# STM32WBA52 register map
File version: 0.1
CPU: CM33 r0p1, little endian, MPU, FPU, 4 interrupt priority bits
Registers are 32-bit, read-write, reset 0x0 unless marked. A register's access mark holds for its fields unless they carry their own. Offsets are from the block's base; [hi:lo] are bit positions; {n}, {i} and the like mark numbered series.

## DBGMCU — Microcontroller debug unit
Base 0xE0044000
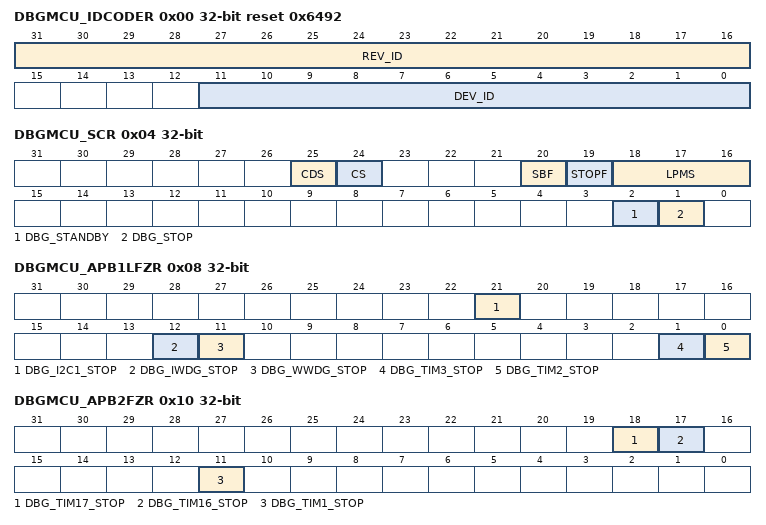
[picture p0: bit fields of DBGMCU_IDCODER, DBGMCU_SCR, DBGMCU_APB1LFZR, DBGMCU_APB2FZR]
0x00 DBGMCU_IDCODER ro reset 0x6492 (reset mask 0xFFFF) — DBGMCU identity code register
  [31:16] REV_ID — Revision ID
    0x1000=Revision A
  [11:0] DEV_ID — Device ID
    0x492=STM32WBA5xxx
0x04 DBGMCU_SCR access per field — DBGMCU status and configuration register
  [25] CDS ro — CPU DeepSleep
    0=CPU not in DeepSleep; 1=CPU in DeepSleep
  [24] CS ro — CPU Sleep
    0=CPU not in Sleep; 1=CPU in Sleep
  [20] SBF ro — Device Standby flag
    0=Device not in Standby mode; 1=Device in Standby mode
  [19] STOPF ro — Device Stop flag
    0=device not in Stop mode; 1=device in Stop mode
  [18:16] LPMS ro — Device low power mode selected 10x: Standby mode others reserved
    0=Stop 0 mode; 1=Stop 1 mode
  [2] DBG_STANDBY rw — Allows debug in Standby mode Write access can be protected by PWR_SECCFGR.LPMSEC. The CPU debug and DBGMCU clocks remain active and the HSI16 oscillator is used as system clock, the supply and SRAM memory content is maintained during Standby debug mode, allowing CPU debug capability. On exit from Standby mode, a standby reset is performed.
    0=Normal Standby mode operation, all clocks are disabled automatically in Stop mode and core is powered down; 1=Core power maintained and CPU debug clock enabled in Standby mode, all other are under reset in Stop mode, except for DBGMCU
  [1] DBG_STOP rw — Allows debug in Stop mode Write access can be protected by PWR_SECCFGR.LPMSEC. The CPU debug and DBGMCU clocks remain active and the HSI16 oscillators is used as system clock during Stop debug mode, allowing CPU debug capability. On exit from Stop mode, the clock settings are set to the Stop mode exit state.
    0=Normal Stop mode operation, all clocks are disabled automatically in Stop mode; 1=CPU debug clock enabled in Stop mode, all other peripheral clocks are disabled automatically in Stop mode, except for DBGMCU
0x08 DBGMCU_APB1LFZR — DBGMCU APB1L peripheral freeze register
  [21] DBG_I2C1_STOP — I2C1 SMBUS timeout stop in CPU debug Write access can be protected by GTZC_TZSC.I2C1SEC.
    0=Normal operation. I2C1 SMBUS timeout continues to operate while CPU is in debug mode.; 1=Stop in debug. I2C1 SMBUS timeout is frozen while CPU is in debug mode.
  [12] DBG_IWDG_STOP — IWDG stop in CPU debug Write access can be protected by GTZC_TZSC.IWDGSEC.
    0=Normal operation. IWDG continues to operate while CPU is in debug mode.; 1=Stop in debug. IWDG is frozen while CPU is in debug mode.
  [11] DBG_WWDG_STOP — WWDG stop in CPU debug Write access can be protected by GTZC_TZSC.WWDGSEC
    0=Normal operation. WWDG continues to operate while CPU is in debug mode.; 1=Stop in debug. WWDG is frozen while CPU is in debug mode.
  [1] DBG_TIM3_STOP — TIM3 stop in CPU debug Write access can be protected by GTZC_TZSC.TIM3SEC.
    0=Normal operation. TIM3 continues to operate while CPU is in debug mode.; 1=Stop in debug. TIM3 is frozen while CPU is in debug mode.
  [0] DBG_TIM2_STOP — TIM2 stop in CPU debug Write access can be protected by GTZC_TZSC.TIM2SEC.
    0=Normal operation. TIM2 continues to operate while CPU is in debug mode.; 1=Stop in debug. TIM2 is frozen while CPU is in debug mode.
0x0C DBGMCU_APB1HFZR — DBGMCU APB1H peripheral freeze register
  [5] DBG_LPTIM2_STOP — LPTIM2 stop in CPU debug Write access can be protected by GTZC_TZSC.LPTIM2SEC.
    0=Normal operation. LPTIM2 continues to operate while CPU is in debug mode.; 1=Stop in debug. LPTIM2 is frozen while CPU is in debug mode.
0x10 DBGMCU_APB2FZR — DBGMCU APB2 peripheral freeze register
  [18] DBG_TIM17_STOP — TIM17 stop in CPU debug Write access can be protected by GTZC_TZSC.TIM17SEC.
    0=Normal operation. TIM17 continues to operate while CPU is in debug mode.; 1=Stop in debug. TIM17 is frozen while CPU is in debug mode.
  [17] DBG_TIM16_STOP — TIM16 stop in CPU debug Write access can be protected by GTZC_TZSC.TIM16SEC.
    0=Normal operation. TIM16 continues to operate while CPU is in debug mode.; 1=Stop in debug. TIM16 is frozen while CPU is in debug mode.
  [11] DBG_TIM1_STOP — TIM1 stop in CPU debug Write access can be protected by GTZC_TZSC.TIM1SEC.
    0=Normal operation. TIM1 continues to operate while CPU is in debug mode.; 1=Stop in debug. TIM1 is frozen while CPU is in debug mode.
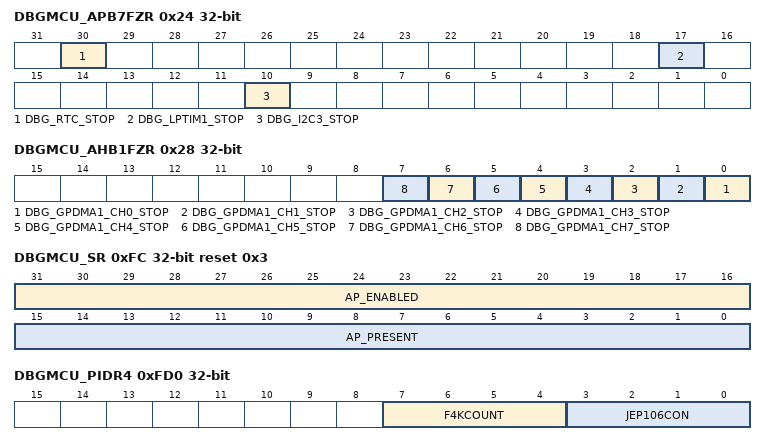
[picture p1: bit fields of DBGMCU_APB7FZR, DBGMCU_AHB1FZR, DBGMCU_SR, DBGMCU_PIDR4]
0x24 DBGMCU_APB7FZR — DBGMCU APB7 peripheral freeze register
  [30] DBG_RTC_STOP — RTC stop in CPU debug Access can be protected by GTZC_TZSC.TIM17SEC. Can only be accessed secure when one or more features in the RTC or TAMP is/are secure.
    0=Normal operation. RTC continues to operate while CPU is in debug mode.; 1=Stop in debug. RTC is frozen while CPU is in debug mode.
  [17] DBG_LPTIM1_STOP — LPTIM1 stop in CPU debug Access can be protected by GTZC_TZSC.LPTIM1SEC.
    0=Normal operation. LPTIM1 continues to operate while CPU is in debug mode.; 1=Stop in debug. LPTIM1 is frozen while CPU is in debug mode.
  [10] DBG_I2C3_STOP — I2C3 stop in CPU debug Access can be protected by GTZC_TZSC.I2C3SEC.
    0=Normal operation. I2C3 continues to operate while CPU is in debug mode.; 1=Stop in debug. I2C3 is frozen while CPU is in debug mode.
0x28 DBGMCU_AHB1FZR — DBGMCU AHB1 peripheral freeze register
  [n] DBG_GPDMA1_CH{n}_STOP (n=0..7) — GPDMA 1 channel {n} stop in CPU debug Write access can be protected by GPDMA_SECCFGR.SEC{n}.
    0=Normal operation. GPDMA 1 channel {n} continues to operate while CPU is in debug mode.; 1=Stop in debug. GPDMA 1 channel {n} is frozen while CPU is in debug mode.
0xFC DBGMCU_SR ro reset 0x3 (reset mask 0xFFF0FFFF) — DBGMCU status register
  [31:16] AP_ENABLED — Bit n identifies whether access port APn is open (can be accessed via the debug port) or locked (debug access to the APn is blocked, except for DBGMCU access) Bit n�=�0: APn locked (except for access to DBGMCU) Bit n�=�1: APn enabled
  [15:0] AP_PRESENT — Bit n identifies whether access port APn is present in device Bit n�=�0: APn absent Bit n�=�1: APn present
0x100 DBGMCU_DBG_AUTH_HOST wo reset not defined — DBGMCU debug host authentication register
  [31:0] AUTH_KEY — Device authentication key The device specific 64-bit authentication key (OEMn key) must be written to this register (in two successive 32-bit writes, least significant word first) to permit RDP regression. Writing a wrong key locks access to the device and prevent code execution from the Flash memory.
0x104 DBGMCU_DBG_AUTH_DEVICE ro reset not defined — DBGMCU debug device authentication register
  [31:0] AUTH_ID — Device specific ID Device specific ID used for RDP regression.
0x7DC DBGMCU_PNCR ro reset not defined — DBGMCU part number codification register
  [31:0] CODIFICATION — Part number codification
    0x323541=STMicroelectronics STM32WBA52xx part number codification
0xFD0 DBGMCU_PIDR4 ro — DBGMCU CoreSight peripheral identity register 4
  [7:4] F4KCOUNT — Register file size
    0=The register file occupies a single 4-Kbyte region
  [3:0] JEP106CON — JEP106 continuation code
    0=STMicroelectronics JEDEC code
0xFE0 DBGMCU_PIDR0 ro — DBGMCU CoreSight peripheral identity register 0
  [7:0] PARTNUM — Part number bits [7:0]
    0=DBGMCU part number
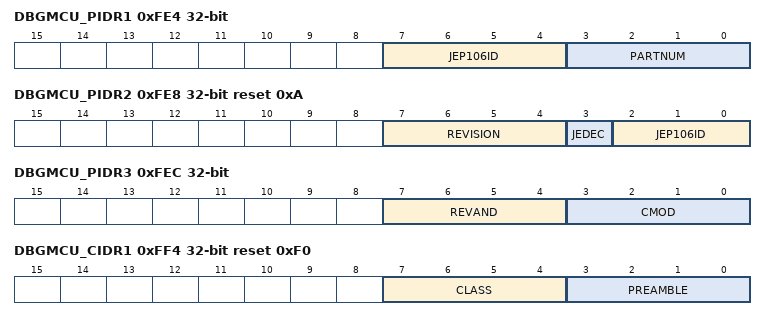
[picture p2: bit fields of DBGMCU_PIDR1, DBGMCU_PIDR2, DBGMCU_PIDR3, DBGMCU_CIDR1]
0xFE4 DBGMCU_PIDR1 ro — DBGMCU CoreSight peripheral identity register 1
  [7:4] JEP106ID — JEP106 identity code bits [3:0]
    0=STMicroelectronics JEDEC code
  [3:0] PARTNUM — Part number bits [11:8]
    0=DBGMCU part number
0xFE8 DBGMCU_PIDR2 ro reset 0xA — DBGMCU CoreSight peripheral identity register 2
  [7:4] REVISION — Component revision number
    0=r0p0
  [3] JEDEC — JEDEC assigned value
    1=Designer identifier specified by JEDEC
  [2:0] JEP106ID — JEP106 identity code bits [6:4]
    2=STMicroelectronics JEDEC code
0xFEC DBGMCU_PIDR3 ro — DBGMCU CoreSight peripheral identity register 3
  [7:4] REVAND — Metal fix version
    0=No metal fix
  [3:0] CMOD — Customer modified
    0=No customer modifications
0xFF0 DBGMCU_CIDR0 ro reset 0xD — DBGMCU CoreSight component identity register 0
  [7:0] PREAMBLE — Component ID bits [7:0]
    13=Common ID value
0xFF4 DBGMCU_CIDR1 ro reset 0xF0 — DBGMCU CoreSight peripheral identity register 1
  [7:4] CLASS — Component ID bits [15:12] - component class
    15=no CoreSight component
  [3:0] PREAMBLE — Component ID bits [11:8]
    0=common ID value
0xFF8 DBGMCU_CIDR2 ro reset 0x5 — DBGMCU CoreSight component identity register 2
  [7:0] PREAMBLE — Component ID bits [23:16]
    5=Common ID value
0xFFC DBGMCU_CIDR3 ro reset 0xB1 — DBGMCU CoreSight component identity register 3
  [7:0] PREAMBLE — Component ID bits [31:24]
    177=Common ID value
